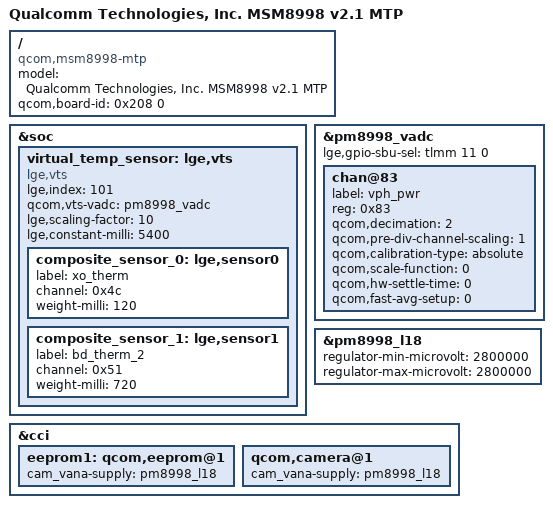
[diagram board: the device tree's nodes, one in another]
/* Copyright (c) 2016, The Linux Foundation. All rights reserved.
 *
 * This program is free software; you can redistribute it and/or modify
 * it under the terms of the GNU General Public License version 2 and
 * only version 2 as published by the Free Software Foundation.
 *
 * This program is distributed in the hope that it will be useful,
 * but WITHOUT ANY WARRANTY; without even the implied warranty of
 * MERCHANTABILITY or FITNESS FOR A PARTICULAR PURPOSE.  See the
 * GNU General Public License for more details.
 */


/dts-v1/;

#include "../../../qcom/msm8998-v2.1.dtsi"
#include "msm8998-phoenix_lao_com.dtsi"

/ {
	model = "Qualcomm Technologies, Inc. MSM8998 v2.1 MTP";
	compatible = "qcom,msm8998-mtp", "qcom,msm8998", "qcom,mtp";
	qcom,board-id = <0x208 0>;
};

&soc {
	/* TODO : tune, vts, 0.12*XO + 0.72*Bd2 + 5.4 */
	virtual_temp_sensor: lge,vts {
		compatible = "lge,vts";
		lge,index = <101>;
		qcom,vts-vadc = <&pm8998_vadc>;
		lge,scaling-factor = <10>;
		lge,constant-milli = <5400>;

		composite_sensor_0: lge,sensor0 {
			label = "xo_therm";
			channel = <0x4c>;
			weight-milli = <120>;
		};

		composite_sensor_1: lge,sensor1 {
			label = "bd_therm_2";
			channel = <0x51>;
			weight-milli = <720>;
		};
	};
};

&pm8998_vadc {
	lge,gpio-sbu-sel = <&tlmm 11 0>;
	chan@83 {
		label = "vph_pwr";
		reg = <0x83>;
		qcom,decimation = <2>;
		qcom,pre-div-channel-scaling = <1>;
		qcom,calibration-type = "absolute";
		qcom,scale-function = <0>;
		qcom,hw-settle-time = <0>;
		qcom,fast-avg-setup = <0>;
    };
};

&pm8998_l18 {
        status = "ok";
        regulator-min-microvolt = <2800000>;
        regulator-max-microvolt = <2800000>;
};

&cci {
        eeprom1: qcom,eeprom@1 {
                cam_vana-supply = <&pm8998_l18>;
	};

        qcom,camera@1 {
                cam_vana-supply = <&pm8998_l18>;
	};
};
